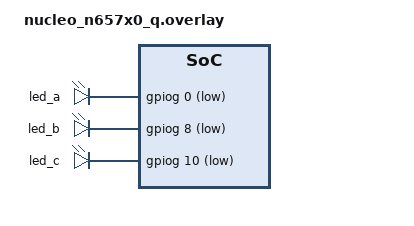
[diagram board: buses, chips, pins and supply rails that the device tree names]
/ {
    aliases {
        leda = &led_a;
        ledb = &led_b;
        ledc = &led_c;
    };

    output_pins {
        compatible = "gpio-leds";

        led_a: op_0 {
            gpios = <&gpiog 0 GPIO_ACTIVE_LOW>;
           
        };

        led_b: op_1 {
            gpios = <&gpiog 8 GPIO_ACTIVE_LOW>;
           
        };
        led_c: op_2 {
            gpios = <&gpiog 10 GPIO_ACTIVE_LOW>;
        };
    };
};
